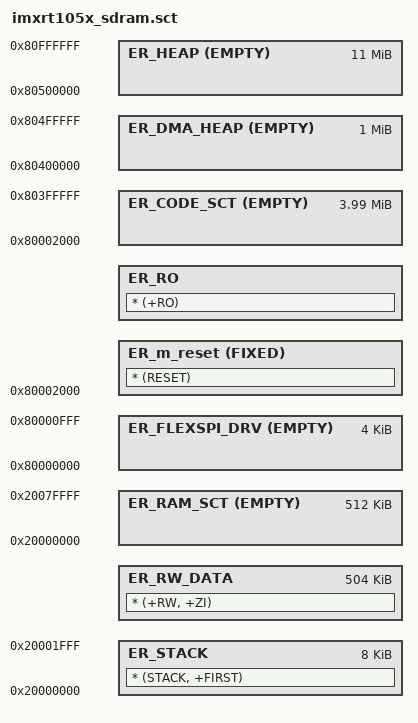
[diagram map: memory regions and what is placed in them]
#! armcc -E

    
#define     CODE_START              0x80002000  /* code start address */
#define     CODE_SIZE               0x3FE000    /* code size: 4088K */

#define     DATA_START              0x20000000  /* data start address */
#define     DATA_SIZE               0x80000     /* code size: 512k */

#define     STACK_START             DATA_START  /* stack start address */
#define     STACK_SIZE              0x2000      /* stack size: 8k */

#define     DMA_HEAP_START          0x80400000  /* dma_heap start address */
#define     DMA_HEAP_SIZE           0x100000    /* dma_heap size: 1M */

#define     HEAP_START              0x80500000  /* heap start address */
#define     HEAP_SIZE               0xB00000    /* heap size: 11M */

#define     FLEXSPI_DRV_START       0x80000000  /* flexspi_drv start address */
#define     FLEXSPI_DRV_SIZE        0x1000      /* flexspi_drv size: 4k */



LR_m_code CODE_START ALIGN 8 CODE_SIZE {
    ER_m_reset CODE_START FIXED {
        * (RESET)
    }

    ER_RO +0 ALIGN 8 {
        * (+RO)
    }

    ER_STACK STACK_START STACK_SIZE{
        * (STACK, +FIRST)
    }

    ER_RW_DATA +0 ALIGN 8 DATA_SIZE-STACK_SIZE {
        * (+RW, +ZI)
    }
}


LR_m_code_section CODE_START OVERLAY CODE_SIZE {
    ER_CODE_SCT +0 EMPTY CODE_SIZE {
    }
}

LR_m_ram_section DATA_START OVERLAY DATA_SIZE {
    ER_RAM_SCT +0 EMPTY DATA_SIZE {
    }
}

LR_m_dma_heap DMA_HEAP_START DMA_HEAP_SIZE {
    ER_DMA_HEAP +0 EMPTY DMA_HEAP_SIZE {
    }
}

LR_m_heap HEAP_START HEAP_SIZE {
    ER_HEAP +0 EMPTY HEAP_SIZE {
    }
}

LR_m_flexspi_drv FLEXSPI_DRV_START FLEXSPI_DRV_SIZE {
    ER_FLEXSPI_DRV +0 EMPTY FLEXSPI_DRV_SIZE {
    }
}





